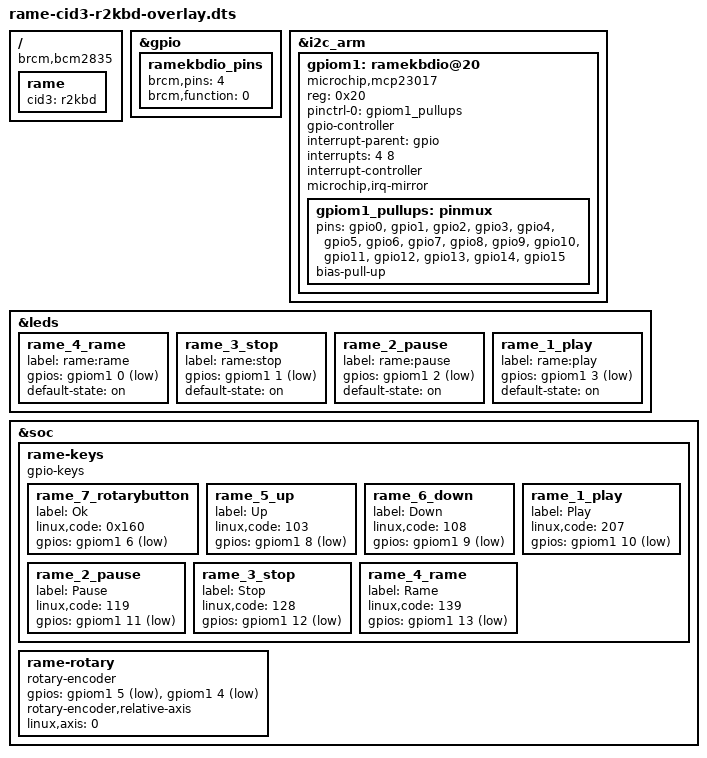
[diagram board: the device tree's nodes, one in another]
// RamePlayer CID3: "R2 Keys" buttons, leds, rotary (r2kbd)
//
// MCP23017 setup based on:
// - https://www.raspberrypi.org/forums/viewtopic.php?f=29&t=104638

/dts-v1/;
/plugin/;

/*
 Rameplayer "R2 Keys" (r2kbd):
+------------------------------------+
|  Up                                |
|  B5   L1    L2    L3    L4         |
|                                    |
|       B1    B2    B3    B4    B7   |
|      Play Pause  Stop  Rame  (rot) |
|  B6                                |
| Down                               |
+------------------------------------+
L1...L4 = Leds
B1...B7 = Buttons
     B7 = Also a rotary
*/

/ {
	// Raspberry Pi 1 and 2
	compatible = "brcm,bcm2835", "brcm,bcm2708", "brcm,bcm2709";

	// component id
	fragment@0 {
		target-path = "/";
		__overlay__ {
			rame {
				cid3 = "r2kbd";
			};
		}; // overlay
	}; // fragment

	// mcp23017 pin setup
	fragment@1 {
		target = <&gpio>;  // /soc/gpio

		__overlay__ {
			ramekbdio_pins: ramekbdio_pins {
				brcm,pins = <4>;
				brcm,function = <0>; // GPIO in
			};
		}; // __overlay__
	}; // fragment

	// mcp23017 IO expander setup
	fragment@2 {
		target = <&i2c_arm>;  // /soc/i2c0 or /soc/i2c1

		__overlay__ {
			status = "okay";
			#address-cells = <1>;
			#size-cells = <0>;

			gpiom1: ramekbdio@20 {
				compatible = "microchip,mcp23017";
				reg = <0x20>;

				pinctrl-names = "default";
				pinctrl-0 = <&gpiom1_pullups>;

				gpio-controller;
				#gpio-cells = <2>;

				interrupt-parent = <&gpio>;
				// INTA->BCM GPIO4, IRQ_TYPE_LEVEL_LOW
				// http://lxr.free-electrons.com/source/include/dt-bindings/interrupt-controller/irq.h?v=4.1#L17
				interrupts = <4 8>;
				interrupt-controller;
				#interrupt-cells=<2>;

				microchip,irq-mirror; // IOCON,0x40

				status = "okay";

				gpiom1_pullups: pinmux {
					pins =	"gpio0", "gpio1", "gpio2", "gpio3",
						"gpio4", "gpio5", "gpio6", "gpio7",
						"gpio8", "gpio9", "gpio10", "gpio11",
						"gpio12", "gpio13", "gpio14", "gpio15";
					bias-pull-up;
				};
			}; // ramekbdio

		}; // __overlay__
	}; // fragment


	// 4 leds, L1...L4
	fragment@3 {
		target = <&leds>;  // /soc/leds

		__overlay__ {
			// http://lxr.free-electrons.com/source/include/dt-bindings/gpio/gpio.h?v=4.1

			// L4
			rame_4_rame {
				label = "rame:rame";
				gpios = <&gpiom1 0 1>; // GPA0 GPIO_ACTIVE_LOW
				default-state = "on";
			};

			// L3
			rame_3_stop {
				label = "rame:stop";
				gpios = <&gpiom1 1 1>; // GPA1 GPIO_ACTIVE_LOW
				default-state = "on";
			};

			// L2
			rame_2_pause {
				label = "rame:pause";
				gpios = <&gpiom1 2 1>; // GPA2 GPIO_ACTIVE_LOW
				default-state = "on";
			};

			// L1
			rame_1_play {
				label = "rame:play";
				gpios = <&gpiom1 3 1>; // GPA3 GPIO_ACTIVE_LOW
				default-state = "on";
			};

		}; // __overlay__
	}; // fragment


	// 7 buttons, B1...B7
	fragment@4 {
		target = <&soc>;  // /soc

		__overlay__ {

			rame-keys {
				compatible = "gpio-keys";
				#address-cells = <1>;
				#size-cells = <0>;
				status = "okay";

				// http://lxr.free-electrons.com/source/include/dt-bindings/input/input.h?v=4.1

				rame_7_rotarybutton {
					label = "Ok";
					linux,code = <0x160>; // KEY_OK (352)
					gpios = <&gpiom1 6 1>; // GPA6 GPIO_ACTIVE_LOW
				};

				rame_5_up {
					label = "Up";
					linux,code = <103>; // KEY_UP
					gpios = <&gpiom1 8 1>; // GPB0 GPIO_ACTIVE_LOW
				};

				rame_6_down {
					label = "Down";
					linux,code = <108>; // KEY_DOWN
					gpios = <&gpiom1 9 1>; // GPB1 GPIO_ACTIVE_LOW
				};

				rame_1_play {
					label = "Play";
					linux,code = <207>; // KEY_PLAY
					gpios = <&gpiom1 10 1>; // GPB2 GPIO_ACTIVE_LOW
				};

				rame_2_pause {
					label = "Pause";
					linux,code = <119>; // KEY_PAUSE
					gpios = <&gpiom1 11 1>; // GPB3 GPIO_ACTIVE_LOW
				};

				rame_3_stop {
					label = "Stop";
					linux,code = <128>; // KEY_STOP
					gpios = <&gpiom1 12 1>; // GPB4 GPIO_ACTIVE_LOW
				};

				rame_4_rame {
					label = "Rame";
					linux,code = <139>; // KEY_MENU
					gpios = <&gpiom1 13 1>; // GPB5 GPIO_ACTIVE_LOW
				};

			}; // rame-keys

			rame-rotary {
				compatible = "rotary-encoder";
				// patched kernel required:
				gpios = <&gpiom1 5 1>, <&gpiom1 4 1>; // GPA5,GPA4
				rotary-encoder,relative-axis;
				linux,axis = <0>; // REL_X
			}; // rame-rotary

		}; // __overlay__
	}; // fragment
};
